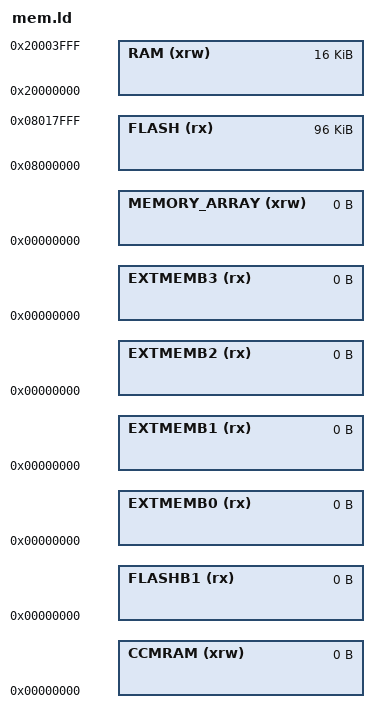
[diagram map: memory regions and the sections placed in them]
/*
 * Memory Spaces Definitions.
 *
 * Need modifying for a specific board. 
 *   FLASH.ORIGIN: starting address of flash
 *   FLASH.LENGTH: length of flash
 *   RAM.ORIGIN: starting address of RAM bank 0
 *   RAM.LENGTH: length of RAM bank 0
 *
 * The values below can be addressed in further linker scripts
 * using functions like 'ORIGIN(RAM)' or 'LENGTH(RAM)'.
 */


_Min_Heap_Size = 0x800;; /* required amount of heap */ 
_Min_Stack_Size = 0x1000;; /* required amount of stack */

MEMORY
{
  RAM (xrw) : ORIGIN = 0x20000000, LENGTH = 16K
  CCMRAM (xrw) : ORIGIN = 0x00000000, LENGTH = 0
  FLASH (rx) : ORIGIN = 0x08000000, LENGTH = 96K
  FLASHB1 (rx) : ORIGIN = 0x00000000, LENGTH = 0
  EXTMEMB0 (rx) : ORIGIN = 0x00000000, LENGTH = 0
  EXTMEMB1 (rx) : ORIGIN = 0x00000000, LENGTH = 0
  EXTMEMB2 (rx) : ORIGIN = 0x00000000, LENGTH = 0
  EXTMEMB3 (rx) : ORIGIN = 0x00000000, LENGTH = 0
  MEMORY_ARRAY (xrw)  : ORIGIN = 0x00000000, LENGTH = 0
}


/*
 * For external ram use something like:

  RAM (xrw) : ORIGIN = 0x68000000, LENGTH = 8K

 */
